# GD32E230 register map
File version: 1.0
CPU: CM23 r0p0, little endian, MPU, FPU, 4 interrupt priority bits
Registers are 32-bit, read-write, reset 0x0 unless marked. A register's access mark holds for its fields unless they carry their own. Offsets are from the block's base; [hi:lo] are bit positions.

## TIMER15 — General-purpose-timers
Base 0x40014400
Same registers: TIMER16 0x40014800
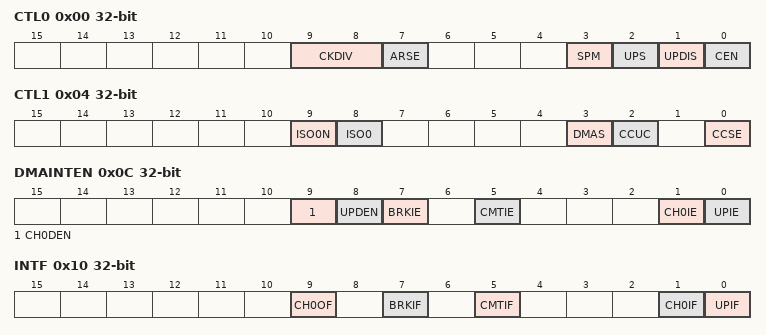
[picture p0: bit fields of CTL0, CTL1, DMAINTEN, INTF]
0x00 CTL0 — control register 0
  [9:8] CKDIV — Clock division
  [7] ARSE — Auto-reload preload enable
  [3] SPM — One-pulse mode
  [2] UPS — Update request source
  [1] UPDIS — Update disable
  [0] CEN — Counter enable
0x04 CTL1 — control register 1
  [9] ISO0N — Output Idle state 0
  [8] ISO0 — Output Idle state 0
  [3] DMAS — Capture/compare DMA selection
  [2] CCUC — Capture/compare control update selection
  [0] CCSE — Capture/compare preloaded control
0x0C DMAINTEN — DMA/Interrupt enable register
  [9] CH0DEN — Capture/Compare 0 DMA request enable
  [8] UPDEN — Update DMA request enable
  [7] BRKIE — Break interrupt enable
  [5] CMTIE — COM interrupt enable
  [1] CH0IE — Capture/Compare 0 interrupt enable
  [0] UPIE — Update interrupt enable
0x10 INTF — interrupt flag register
  [9] CH0OF — Capture/Compare 0 overcapture flag
  [7] BRKIF — Break interrupt flag
  [5] CMTIF — COM interrupt flag
  [1] CH0IF — Capture/compare 0 interrupt flag
  [0] UPIF — Update interrupt flag
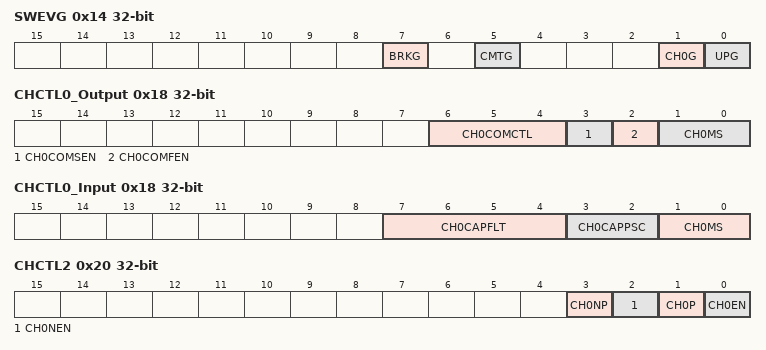
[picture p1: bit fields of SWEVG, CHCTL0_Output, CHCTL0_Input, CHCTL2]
0x14 SWEVG wo — event generation register
  [7] BRKG — Break generation
  [5] CMTG — Capture/Compare control update generation
  [1] CH0G — Capture/compare 0 generation
  [0] UPG — Update generation
0x18 CHCTL0_Output — capture/compare mode register (output mode)
  [6:4] CH0COMCTL — Output Compare 0 mode
  [3] CH0COMSEN — Output Compare 0 preload enable
  [2] CH0COMFEN — Output Compare 0 fast enable
  [1:0] CH0MS — Capture/Compare 0 selection
0x18 CHCTL0_Input (alternate view of CHCTL0_Output) — capture/compare mode register 0 (input mode)
  [7:4] CH0CAPFLT — Input capture 0 filter
  [3:2] CH0CAPPSC — Input capture 0 prescaler
  [1:0] CH0MS — Capture/Compare 0 selection
0x20 CHCTL2 — capture/compare enable register
  [3] CH0NP — Capture/Compare 0 output Polarity
  [2] CH0NEN — Capture/Compare 0 complementary output enable
  [1] CH0P — Capture/Compare 0 output Polarity
  [0] CH0EN — Capture/Compare 0 output enable
0x24 CNT — counter
  [15:0] CNT — counter value
0x28 PSC — prescaler
  [15:0] PSC — Prescaler value
0x2C CAR — auto-reload register
  [15:0] CARL — Auto-reload value
0x30 CREP — repetition counter register
  [7:0] CREP — Repetition counter value
0x34 CH0CV — capture/compare register 0
  [15:0] CH0VAL — Capture/Compare 0 value
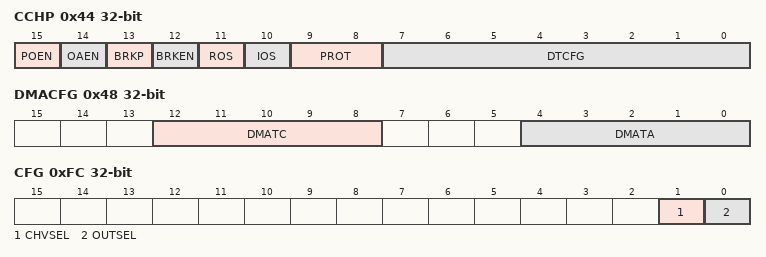
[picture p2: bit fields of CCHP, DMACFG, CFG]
0x44 CCHP — break and dead-time register
  [15] POEN — Main output enable
  [14] OAEN — Automatic output enable
  [13] BRKP — Break polarity
  [12] BRKEN — Break enable
  [11] ROS — Off-state selection for Run mode
  [10] IOS — Off-state selection for Idle mode
  [9:8] PROT — complementary register protect control
  [7:0] DTCFG — Dead-time generator setup
0x48 DMACFG — DMA configuration register
  [12:8] DMATC — DMA transfer count
  [4:0] DMATA — DMA transfer access start address
0x4C DMATB — DMA transfer buffer register
  [15:0] DMATB — DMA register for burst accesses
0xFC CFG — configuration register
  [1] CHVSEL — Write CHxVAL register selection
  [0] OUTSEL — The output value selection

## WWDGT — Window watchdog timer
Base 0x40002C00
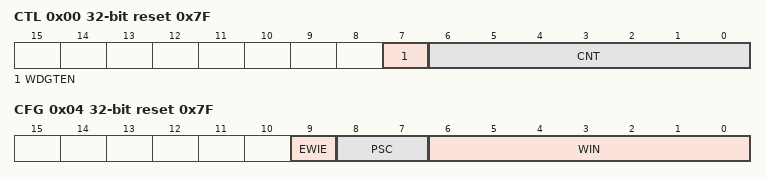
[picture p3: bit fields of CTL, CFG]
0x00 CTL reset 0x7F — Control register
  [7] WDGTEN — Activation bit
  [6:0] CNT — 7-bit counter
0x04 CFG reset 0x7F — Configuration register
  [9] EWIE — Early wakeup interrupt
  [8:7] PSC — Prescaler
  [6:0] WIN — 7-bit window value
0x08 STAT — Status register
  [0] EWIF — Early wakeup interrupt flag

## CoreDebug — Debug Control Block
Base 0xE000EDF0; register names take the prefix CoreDebug_
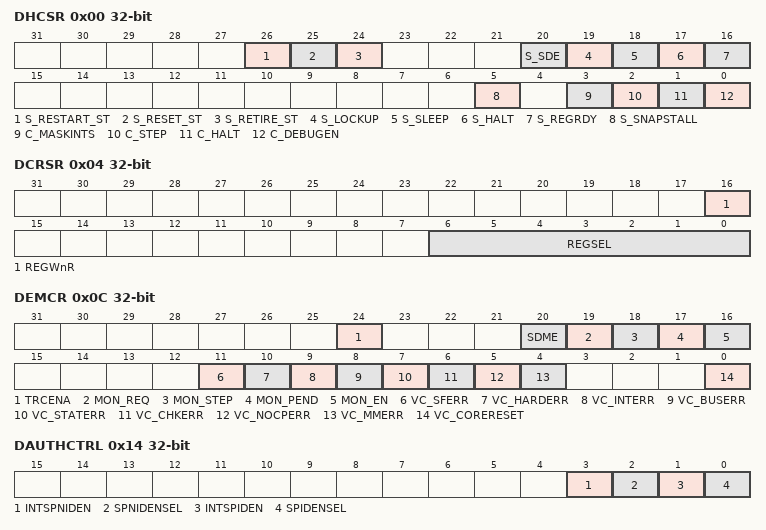
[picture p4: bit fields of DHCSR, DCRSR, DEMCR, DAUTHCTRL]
0x00 DHCSR access not given — Debug Halting Control and Status Register
  [26] S_RESTART_ST — Restart sticky status
  [25] S_RESET_ST — Reset sticky status
  [24] S_RETIRE_ST — Retire sticky status
  [20] S_SDE — Secure debug enabled
  [19] S_LOCKUP — Lockup status
  [18] S_SLEEP — Sleeping status
  [17] S_HALT — Halted status
  [16] S_REGRDY — Register ready status
  [5] S_SNAPSTALL — Snap stall control
  [3] C_MASKINTS — Mask PendSV, SysTick and external configurable interrupts
  [2] C_STEP — Enable single step
  [1] C_HALT — Halt processor
  [0] C_DEBUGEN — Enable Halting debug
0x04 DCRSR wo — Debug Core Register Select Register
  [16] REGWnR — Register write/not-read access
  [6:0] REGSEL — Register selector
0x0C DEMCR access not given — Debug Exception and Monitor Control Register
  [24] TRCENA — Global DWT and ITM features enable
  [20] SDME — Secure DebugMonitor enable
  [19] MON_REQ — DebugMonitor semaphore bit
  [18] MON_STEP — Enable DebugMonitor stepping
  [17] MON_PEND — DebugMonitor pending state
  [16] MON_EN — DebugMonitor enable
  [11] VC_SFERR — SecureFault exception Halting debug vector catch enable
  [10] VC_HARDERR — HardFault exception Halting debug vector catch enable
  [9] VC_INTERR — Excception entry and return faults Halting debug vector catch enable
  [8] VC_BUSERR — BusFault exception Halting debug vector catch enable
  [7] VC_STATERR — UsageFault exception state information error Halting debug vector catch enable
  [6] VC_CHKERR — UsageFault exception checking error Halting debug vector catch enable
  [5] VC_NOCPERR — UsageFault exception coprocessor access Halting debug vector catch enable
  [4] VC_MMERR — MemManage exception Halting debug vector catch enable
  [0] VC_CORERESET — Core reset Halting debug vector catch enable
0x14 DAUTHCTRL access not given — Debug Authentication Control Register
  [3] INTSPNIDEN — Internal Secure non-invasive debug enable
  [2] SPNIDENSEL — Secure non-invasive debug enable select
  [1] INTSPIDEN — Internal Secure invasive debug enable
  [0] SPIDENSEL — Secure invasive debug enable select
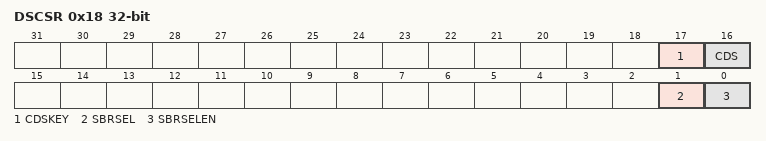
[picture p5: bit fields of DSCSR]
0x18 DSCSR access not given — Debug Security Control and Status Register
  [17] CDSKEY — CDS field write-enable key
  [16] CDS — Current domain Secure
  [1] SBRSEL — Secure Banked register select
  [0] SBRSELEN — Secure Banked register select enable
